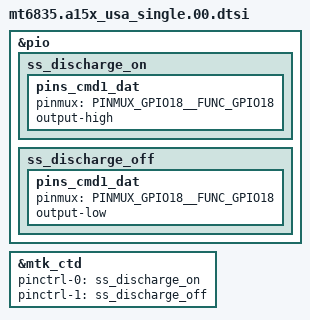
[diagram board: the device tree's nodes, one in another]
/* 
 * Generated by Samsung 
 * If these files should be changed, then please make a sync with MTK
*/

#include "mt6835-a15x_common.dtsi"
#include "mt6835-a15x_camera_00.dtsi"

&pio {
	ss_discharge_on: ss_discharge_on {
		pins_cmd1_dat {
			pinmux = <PINMUX_GPIO18__FUNC_GPIO18>;
			output-high;
		};
	};
	ss_discharge_off: ss_discharge_off {
		pins_cmd1_dat {
			pinmux = <PINMUX_GPIO18__FUNC_GPIO18>;
			output-low;
		};
	};
};

&mtk_ctd {
	pinctrl-names = "ss_discharge_on", "ss_discharge_off";
	pinctrl-0 = <&ss_discharge_on>;
	pinctrl-1 = <&ss_discharge_off>;
};

/*End of this file, DO NOT ADD ANYTHING HERE*/
